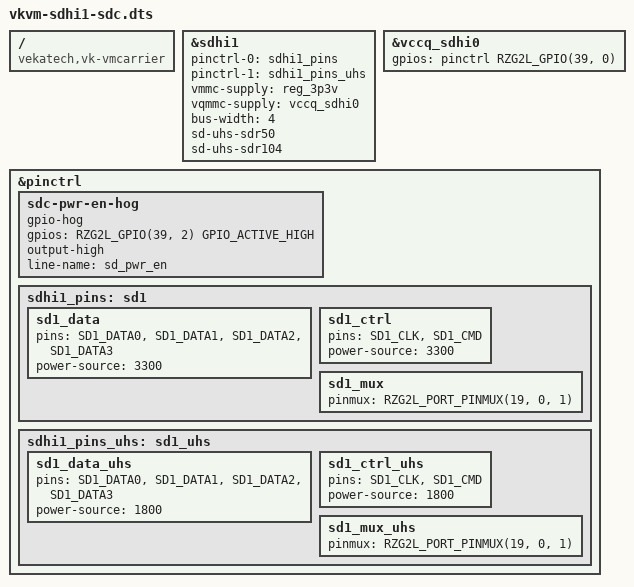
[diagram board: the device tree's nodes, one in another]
/*
 * Copyright 2026 Vekatech
 *
 * This program is free software; you can redistribute it and/or
 * modify it under the terms of the GNU General Public License
 * as published by the Free Software Foundation; either version 2
 * of the License, or (at your option) any later version.
 *
 * This program is distributed in the hope that it will be useful,
 * but WITHOUT ANY WARRANTY; without even the implied warranty of
 * MERCHANTABILITY or FITNESS FOR A PARTICULAR PURPOSE. See the
 * GNU General Public License for more details.
 */

/dts-v1/;
/plugin/;

#include <dt-bindings/pinctrl/rzg2l-pinctrl.h>
#include <dt-bindings/gpio/gpio.h>

/{
	compatible = "vekatech,vk-vmcarrier", 
	             "renesas,r9a07g044l2", 
		     "renesas,r9a07g044";
};

&sdhi1 {
	pinctrl-0 = <&sdhi1_pins>;
	pinctrl-1 = <&sdhi1_pins_uhs>;
	pinctrl-names = "default", "state_uhs";

	vmmc-supply = <&reg_3p3v>;
	vqmmc-supply = <&vccq_sdhi0>;
	bus-width = <4>;
	sd-uhs-sdr50;
	sd-uhs-sdr104;
	status = "okay";
};

&vccq_sdhi0 {
	gpios = <&pinctrl RZG2L_GPIO(39, 0) GPIO_ACTIVE_HIGH>;
};

&pinctrl {
	sdc-pwr-en-hog {
		gpio-hog;
		gpios = <RZG2L_GPIO(39, 2) GPIO_ACTIVE_HIGH>;
		output-high;
		line-name = "sd_pwr_en";
	};

	sdhi1_pins: sd1 {
		sd1_data {
			pins = "SD1_DATA0", "SD1_DATA1", "SD1_DATA2", "SD1_DATA3";
			power-source  = <3300>;
		};

		sd1_ctrl {
			pins = "SD1_CLK", "SD1_CMD";
			power-source  = <3300>;
		};

		sd1_mux {
			pinmux = <RZG2L_PORT_PINMUX(19, 0, 1)>; /* CD */
		};
	};

	sdhi1_pins_uhs: sd1_uhs {
		sd1_data_uhs {
			pins = "SD1_DATA0", "SD1_DATA1", "SD1_DATA2", "SD1_DATA3";
			power-source = <1800>;
		};

		sd1_ctrl_uhs {
			pins = "SD1_CLK", "SD1_CMD";
			power-source = <1800>;
		};

		sd1_mux_uhs {
			pinmux = <RZG2L_PORT_PINMUX(19, 0, 1)>; /* SD1_CD */
		};
	};
};

